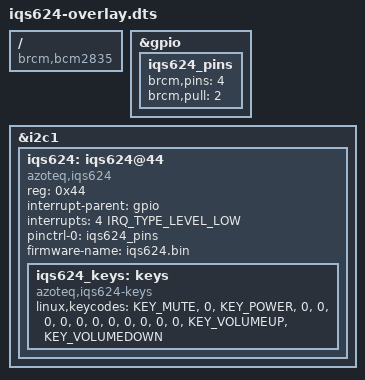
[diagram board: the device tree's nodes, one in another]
// SPDX-License-Identifier: GPL-2.0-or-later
// Definitions for Azoteq IQS624 multi-function sensor
/dts-v1/;
/plugin/;
#include <dt-bindings/input/input.h>
#include <dt-bindings/interrupt-controller/irq.h>

/ {
	compatible = "brcm,bcm2835";

	fragment@0 {
		target = <&gpio>;
		__overlay__ {
			iqs624_pins: iqs624_pins {
				brcm,pins = <4>;
				brcm,pull = <2>;
			};
		};
	};

	fragment@1 {
		target = <&i2c1>;
		__overlay__ {
			#address-cells = <1>;
			#size-cells = <0>;
			status = "okay";

			iqs624: iqs624@44 {
				compatible = "azoteq,iqs624";
				reg = <0x44>;
				interrupt-parent = <&gpio>;
				interrupts = <4 IRQ_TYPE_LEVEL_LOW>;
				pinctrl-names = "default";
				pinctrl-0 = <&iqs624_pins>;
				firmware-name = "iqs624.bin";

				iqs624_keys: keys {
					compatible = "azoteq,iqs624-keys";
					linux,keycodes = <KEY_MUTE>,
							 <0>,
							 <KEY_POWER>,
							 <0>,
							 <0>,
							 <0>,
							 <0>,
							 <0>,
							 <0>,
							 <0>,
							 <0>,
							 <0>,
							 <0>,
							 <0>,
							 <KEY_VOLUMEUP>,
							 <KEY_VOLUMEDOWN>;
				};
			};
		};
	};

	__overrides__ {
		interrupt = <&iqs624_pins>,"brcm,pins:0",
			    <&iqs624>,"interrupts:0";
		config = <&iqs624>,"firmware-name";
	};
};
